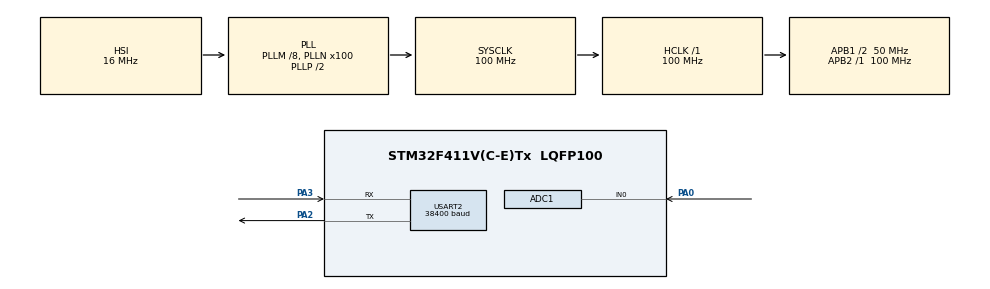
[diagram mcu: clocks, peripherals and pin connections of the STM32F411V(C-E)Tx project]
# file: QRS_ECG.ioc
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ADC1.Channel-2\#ChannelRegularConversion=ADC_CHANNEL_0
ADC1.ContinuousConvMode=ENABLE
ADC1.DMAContinuousRequests=ENABLE
ADC1.ExternalTrigConv=ADC_SOFTWARE_START
ADC1.NbrOfConversionFlag=1
ADC1.Rank-2\#ChannelRegularConversion=1
ADC1.SamplingTime-2\#ChannelRegularConversion=ADC_SAMPLETIME_480CYCLES
ADC1.master=1
Dma.ADC1.0.Direction=DMA_PERIPH_TO_MEMORY
Dma.ADC1.0.FIFOMode=DMA_FIFOMODE_DISABLE
Dma.ADC1.0.Instance=DMA2_Stream0
Dma.ADC1.0.MemDataAlignment=DMA_MDATAALIGN_HALFWORD
Dma.ADC1.0.MemInc=DMA_MINC_ENABLE
Dma.ADC1.0.Mode=DMA_CIRCULAR
Dma.ADC1.0.PeriphDataAlignment=DMA_PDATAALIGN_HALFWORD
Dma.ADC1.0.PeriphInc=DMA_PINC_DISABLE
Dma.ADC1.0.Priority=DMA_PRIORITY_LOW
Dma.Request0=ADC1
Mcu.Family=STM32F4
Mcu.Name=STM32F411V(C-E)Tx
Mcu.Package=LQFP100
NVIC.DMA2_Stream0_IRQn=true\:0\:0\:false\:false\:true\:false\:true\:true
NVIC.PriorityGroup=NVIC_PRIORITYGROUP_0
NVIC.TIM2_IRQn=true\:0\:0\:false\:false\:true\:true\:true\:true
PA0-WKUP.Signal=ADCx_IN0
PA13.Mode=Serial_Wire
PA13.Signal=SYS_JTMS-SWDIO
PA14.Mode=Serial_Wire
PA14.Signal=SYS_JTCK-SWCLK
PA2.Mode=Asynchronous
PA2.Signal=USART2_TX
PA3.Mode=Asynchronous
PA3.Signal=USART2_RX
PH0\ -\ OSC_IN.Mode=HSE-External-Oscillator
PH0\ -\ OSC_IN.Signal=RCC_OSC_IN
PH1\ -\ OSC_OUT.Mode=HSE-External-Oscillator
PH1\ -\ OSC_OUT.Signal=RCC_OSC_OUT
ProjectManager.HeapSize=0x200
ProjectManager.StackSize=0x400
ProjectManager.TargetToolchain=STM32CubeIDE
RCC.48MHZClocksFreq_Value=25000000
RCC.AHBFreq_Value=100000000
RCC.APB1CLKDivider=RCC_HCLK_DIV2
RCC.APB1Freq_Value=50000000
RCC.APB1TimFreq_Value=100000000
RCC.APB2Freq_Value=100000000
RCC.APB2TimFreq_Value=100000000
RCC.CortexFreq_Value=100000000
RCC.HCLKFreq_Value=100000000
RCC.HSE_VALUE=8000000
RCC.HSI_VALUE=16000000
RCC.LSE_VALUE=32768
RCC.PLLI2SM=5
RCC.PLLI2SN=200
RCC.PLLM=8
RCC.PLLN=100
RCC.PLLQ=8
RCC.SYSCLKFreq_VALUE=100000000
RCC.SYSCLKSource=RCC_SYSCLKSOURCE_PLLCLK
RCC.VCOOutputFreq_Value=200000000
SH.ADCx_IN0.0=ADC1_IN0,IN0
TIM2.Period=250
TIM2.Prescaler=1999
TIM2.TIM_MasterOutputTrigger=TIM_TRGO_RESET
USART2.BaudRate=38400
USART2.VirtualMode=VM_ASYNC
VP_TIM2_VS_ClockSourceINT.Mode=Internal
board=STM32F411E-DISCO

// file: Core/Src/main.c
/**
 * @file       main.c
 * @copyright  Copyright (C) 2025 HCMUS. All rights reserved.
 * @license    This project is released under the VB's License.
 * @version    1.0.8
 * @date       2025-06-23
 * @author     Binh Nguyen
 *
 * @brief      main
 *
 */

/* Includes ----------------------------------------------------------- */
#include <stdio.h>
#include <string.h>
#include "main.h"
#include "mylib.h"
#include "filter.h"
#include "cbuffer.h"

/* USER CODE BEGIN PTD */
BandpassFilter bandpass_filter;
cbuffer_t adc_buffer;
uint8_t adc_buffer_data[4096];
/* USER CODE END PTD */

/* USER CODE BEGIN PD */
#define START_BYTE 0xAA
#define END_BYTE 0xBB
/* USER CODE END PD */

ADC_HandleTypeDef hadc1;
DMA_HandleTypeDef hdma_adc1;

TIM_HandleTypeDef htim2;

UART_HandleTypeDef huart2;

/* USER CODE BEGIN PV */
uint8_t sendBuffer[FRAME_SIZE];
/* USER CODE END PV */

void SystemClock_Config(void);
static void MX_GPIO_Init(void);
static void MX_DMA_Init(void);
static void MX_ADC1_Init(void);
static void MX_USART2_UART_Init(void);
static void MX_TIM2_Init(void);

int main(void)
{

  /* MCU Configuration--------------------------------------------------------*/

  /* Reset of all peripherals, Initializes the Flash interface and the Systick. */
  HAL_Init();

  /* Configure the system clock */
  SystemClock_Config();

  /* Initialize all configured peripherals */
  MX_GPIO_Init();
  MX_DMA_Init();
  MX_ADC1_Init();
  MX_USART2_UART_Init();
  MX_TIM2_Init();
  /* USER CODE BEGIN 2 */
  BandpassFilter_Init(&bandpass_filter);
  cb_init(&adc_buffer, adc_buffer_data, sizeof(adc_buffer_data));
  HAL_TIM_Base_Start_IT(&htim2);
  HAL_ADC_Start_DMA(&hadc1, &ADC_value, 1);
  HAL_ADC_Start_IT(&hadc1);

  /* USER CODE END 2 */

  /* Infinite loop */
  while (1)
  {

    /* USER CODE BEGIN 3 */
    if (send_flag == 1)
    {
      send_flag = 0;
      uint8_t temp_buffer[256];
      uint32_t bytes_read = cb_read(&adc_buffer, temp_buffer, 256);
      if (bytes_read == 256)
      {
        int idx = 0;
        sendBuffer[idx++] = START_BYTE;

        for (int i = 0; i < 64; i++)
        {
          uint16_t raw_value = (temp_buffer[i * 4] << 8) | temp_buffer[i * 4 + 1];
          sendBuffer[idx++] = (raw_value >> 8) & 0xFF;
          sendBuffer[idx++] = raw_value & 0xFF;
        }

        for (int i = 0; i < 64; i++)
        {
          int16_t bp_value = (temp_buffer[i * 4 + 2] << 8) | temp_buffer[i * 4 + 3];
          sendBuffer[idx++] = (bp_value >> 8) & 0xFF;
          sendBuffer[idx++] = bp_value & 0xFF;
        }

        uint8_t checksum = 0;
        for (int i = 1; i < idx; i++)
        {
          checksum += sendBuffer[i];
        }
        sendBuffer[idx++] = checksum;

        sendBuffer[idx++] = END_BYTE;

        HAL_UART_Transmit(&huart2, sendBuffer, idx, 200);
      }
      else
      {
        char error_msg[] = "Error reading from buffer\n";
        HAL_UART_Transmit(&huart2, (uint8_t*)error_msg, strlen(error_msg), 200);
      }
    }
  }
  /* USER CODE END 3 */
}

void SystemClock_Config(void)
{
  RCC_OscInitTypeDef RCC_OscInitStruct = {0};
  RCC_ClkInitTypeDef RCC_ClkInitStruct = {0};

  /** Configure the main internal regulator output voltage
  */
  __HAL_RCC_PWR_CLK_ENABLE();
  __HAL_PWR_VOLTAGESCALING_CONFIG(PWR_REGULATOR_VOLTAGE_SCALE1);

  /** Initializes the RCC Oscillators according to the specified parameters
  * in the RCC_OscInitTypeDef structure.
  */
  RCC_OscInitStruct.OscillatorType = RCC_OSCILLATORTYPE_HSI;
  RCC_OscInitStruct.HSIState = RCC_HSI_ON;
  RCC_OscInitStruct.HSICalibrationValue = RCC_HSICALIBRATION_DEFAULT;
  RCC_OscInitStruct.PLL.PLLState = RCC_PLL_ON;
  RCC_OscInitStruct.PLL.PLLSource = RCC_PLLSOURCE_HSI;
  RCC_OscInitStruct.PLL.PLLM = 8;
  RCC_OscInitStruct.PLL.PLLN = 100;
  RCC_OscInitStruct.PLL.PLLP = RCC_PLLP_DIV2;
  RCC_OscInitStruct.PLL.PLLQ = 8;
  if (HAL_RCC_OscConfig(&RCC_OscInitStruct) != HAL_OK)
  {
    Error_Handler();
  }

  /** Initializes the CPU, AHB and APB buses clocks
  */
  RCC_ClkInitStruct.ClockType = RCC_CLOCKTYPE_HCLK|RCC_CLOCKTYPE_SYSCLK
                              |RCC_CLOCKTYPE_PCLK1|RCC_CLOCKTYPE_PCLK2;
  RCC_ClkInitStruct.SYSCLKSource = RCC_SYSCLKSOURCE_PLLCLK;
  RCC_ClkInitStruct.AHBCLKDivider = RCC_SYSCLK_DIV1;
  RCC_ClkInitStruct.APB1CLKDivider = RCC_HCLK_DIV2;
  RCC_ClkInitStruct.APB2CLKDivider = RCC_HCLK_DIV1;

  if (HAL_RCC_ClockConfig(&RCC_ClkInitStruct, FLASH_LATENCY_3) != HAL_OK)
  {
    Error_Handler();
  }
}

static void MX_ADC1_Init(void)
{
  ADC_ChannelConfTypeDef sConfig = {0};

  hadc1.Instance = ADC1;
  hadc1.Init.ClockPrescaler = ADC_CLOCK_SYNC_PCLK_DIV4;
  hadc1.Init.Resolution = ADC_RESOLUTION_12B;
  hadc1.Init.ScanConvMode = DISABLE;
  hadc1.Init.ContinuousConvMode = ENABLE;
  hadc1.Init.DiscontinuousConvMode = DISABLE;
  hadc1.Init.ExternalTrigConvEdge = ADC_EXTERNALTRIGCONVEDGE_NONE;
  hadc1.Init.ExternalTrigConv = ADC_SOFTWARE_START;
  hadc1.Init.DataAlign = ADC_DATAALIGN_RIGHT;
  hadc1.Init.NbrOfConversion = 1;
  hadc1.Init.DMAContinuousRequests = ENABLE;
  hadc1.Init.EOCSelection = ADC_EOC_SINGLE_CONV;
  if (HAL_ADC_Init(&hadc1) != HAL_OK)
  {
    Error_Handler();
  }

  sConfig.Channel = ADC_CHANNEL_0;
  sConfig.Rank = 1;
  sConfig.SamplingTime = ADC_SAMPLETIME_480CYCLES;
  if (HAL_ADC_ConfigChannel(&hadc1, &sConfig) != HAL_OK)
  {
    Error_Handler();
  }
}

static void MX_TIM2_Init(void)
{
  TIM_ClockConfigTypeDef sClockSourceConfig = {0};
  TIM_MasterConfigTypeDef sMasterConfig = {0};

  htim2.Instance = TIM2;
  htim2.Init.Prescaler = 1999;
  htim2.Init.CounterMode = TIM_COUNTERMODE_UP;
  htim2.Init.Period = 250;
  htim2.Init.ClockDivision = TIM_CLOCKDIVISION_DIV1;
  htim2.Init.AutoReloadPreload = TIM_AUTORELOAD_PRELOAD_DISABLE;
  if (HAL_TIM_Base_Init(&htim2) != HAL_OK)
  {
    Error_Handler();
  }
  sClockSourceConfig.ClockSource = TIM_CLOCKSOURCE_INTERNAL;
  if (HAL_TIM_ConfigClockSource(&htim2, &sClockSourceConfig) != HAL_OK)
  {
    Error_Handler();
  }
  sMasterConfig.MasterOutputTrigger = TIM_TRGO_RESET;
  sMasterConfig.MasterSlaveMode = TIM_MASTERSLAVEMODE_DISABLE;
  if (HAL_TIMEx_MasterConfigSynchronization(&htim2, &sMasterConfig) != HAL_OK)
  {
    Error_Handler();
  }
}

static void MX_USART2_UART_Init(void)
{
  huart2.Instance = USART2;
  huart2.Init.BaudRate = 38400;
  huart2.Init.WordLength = UART_WORDLENGTH_8B;
  huart2.Init.StopBits = UART_STOPBITS_1;
  huart2.Init.Parity = UART_PARITY_NONE;
  huart2.Init.Mode = UART_MODE_TX_RX;
  huart2.Init.HwFlowCtl = UART_HWCONTROL_NONE;
  huart2.Init.OverSampling = UART_OVERSAMPLING_16;
  if (HAL_UART_Init(&huart2) != HAL_OK)
  {
    Error_Handler();
  }
}

static void MX_DMA_Init(void)
{
  /* DMA controller clock enable */
  __HAL_RCC_DMA2_CLK_ENABLE();

  /* DMA interrupt init */
  /* DMA2_Stream0_IRQn interrupt configuration */
  HAL_NVIC_SetPriority(DMA2_Stream0_IRQn, 0, 0);
  HAL_NVIC_EnableIRQ(DMA2_Stream0_IRQn);
}

static void MX_GPIO_Init(void)
{
  /* GPIO Ports Clock Enable */
  __HAL_RCC_GPIOH_CLK_ENABLE();
  __HAL_RCC_GPIOA_CLK_ENABLE();
}

void Error_Handler(void)
{
  __disable_irq();
  while (1)
  {
  }
}
